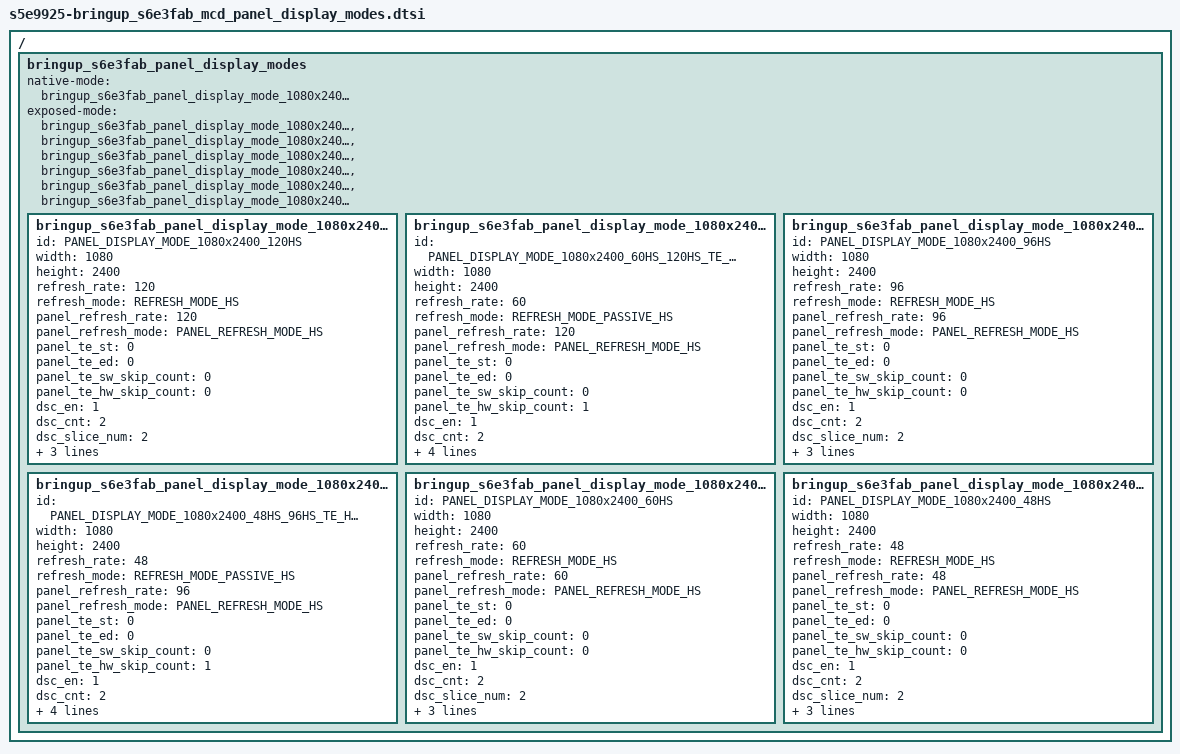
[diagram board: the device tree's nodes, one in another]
/*
 * SAMSUNG LCD Panel Device Tree Source
 *
 * Copyright (c) 2020 Samsung Electronics Co., Ltd.
 *		http://www.samsung.com
 *
 * This program is free software; you can redistribute it and/or modify
 * it under the terms of the GNU General Public License version 2 as
 * published by the Free Software Foundation.
 */

#include <dt-bindings/display/panel-display.h>

/ {
	fragment@panel_display_mode {
		target-path = "/";
		__overlay__ {
			bringup_s6e3fab_panel_display_modes:
			bringup_s6e3fab_panel_display_modes {
				native-mode = <&bringup_s6e3fab_panel_display_mode_1080x2400_120hs>;
				exposed-mode = <
					&bringup_s6e3fab_panel_display_mode_1080x2400_120hs
					&bringup_s6e3fab_panel_display_mode_1080x2400_60hs_120hs
					&bringup_s6e3fab_panel_display_mode_1080x2400_96hs
					&bringup_s6e3fab_panel_display_mode_1080x2400_48hs_96hs
					&bringup_s6e3fab_panel_display_mode_1080x2400_60hs
					&bringup_s6e3fab_panel_display_mode_1080x2400_48hs
				>;

				/* fhd */
				bringup_s6e3fab_panel_display_mode_1080x2400_120hs:
				bringup_s6e3fab_panel_display_mode_1080x2400_120hs {
					id = PANEL_DISPLAY_MODE_1080x2400_120HS;
					width = <1080>;
					height = <2400>;
					/* timing parameters */
					refresh_rate = <120>;			/* logical refresh rate */
					refresh_mode = <REFRESH_MODE_HS>;
					panel_refresh_rate = <120>;		/* panel internal refresh rate */
					panel_refresh_mode = <PANEL_REFRESH_MODE_HS>;
					panel_te_st = <0>;				/* te rising */
					panel_te_ed = <0>;				/* te falling */
					panel_te_sw_skip_count = <0>;	/* s/w te modulation */
					panel_te_hw_skip_count = <0>;	/* h/w te modulation */
					/* dsc parameters */
					dsc_en = <1>;			/* 0:Disable, 1:Enable */
					dsc_cnt = <2>;			/* used DSC count */
					dsc_slice_num = <2>;	/* count of dsc slice */
					dsc_slice_w = <540>;	/* width of dsc slice */
					dsc_slice_h = <120>;	/* height of dsc slice */
					/* dsi parameters */
					cmd_lp_ref = <3337>;
				};

				bringup_s6e3fab_panel_display_mode_1080x2400_60hs_120hs:
				bringup_s6e3fab_panel_display_mode_1080x2400_60hs_120hs {
					id = PANEL_DISPLAY_MODE_1080x2400_60HS_120HS_TE_HW_SKIP_1;
					width = <1080>;
					height = <2400>;
					/* timing parameters */
					refresh_rate = <60>;			/* logical refresh rate */
					refresh_mode = <REFRESH_MODE_PASSIVE_HS>;
					panel_refresh_rate = <120>;		/* panel internal refresh rate */
					panel_refresh_mode = <PANEL_REFRESH_MODE_HS>;
					panel_te_st = <0>;				/* te rising */
					panel_te_ed = <0>;				/* te falling */
					panel_te_sw_skip_count = <0>;	/* s/w te modulation */
					panel_te_hw_skip_count = <1>;	/* h/w te modulation */
					/* dsc parameters */
					dsc_en = <1>;			/* 0:Disable, 1:Enable */
					dsc_cnt = <2>;			/* used DSC count */
					dsc_slice_num = <2>;	/* count of dsc slice */
					dsc_slice_w = <540>;	/* width of dsc slice */
					dsc_slice_h = <120>;	/* height of dsc slice */
					/* dsi parameters */
					cmd_lp_ref = <3337>;
				};

				bringup_s6e3fab_panel_display_mode_1080x2400_96hs:
				bringup_s6e3fab_panel_display_mode_1080x2400_96hs {
					id = PANEL_DISPLAY_MODE_1080x2400_96HS;
					width = <1080>;
					height = <2400>;
					/* timing parameters */
					refresh_rate = <96>;			/* logical refresh rate */
					refresh_mode = <REFRESH_MODE_HS>;
					panel_refresh_rate = <96>;		/* panel internal refresh rate */
					panel_refresh_mode = <PANEL_REFRESH_MODE_HS>;
					panel_te_st = <0>;				/* te rising */
					panel_te_ed = <0>;				/* te falling */
					panel_te_sw_skip_count = <0>;	/* s/w te modulation */
					panel_te_hw_skip_count = <0>;	/* h/w te modulation */
					/* dsc parameters */
					dsc_en = <1>;			/* 0:Disable, 1:Enable */
					dsc_cnt = <2>;			/* used DSC count */
					dsc_slice_num = <2>;	/* count of dsc slice */
					dsc_slice_w = <540>;	/* width of dsc slice */
					dsc_slice_h = <120>;	/* height of dsc slice */
					/* dsi parameters */
					cmd_lp_ref = <5093>;
				};

				bringup_s6e3fab_panel_display_mode_1080x2400_48hs_96hs:
				bringup_s6e3fab_panel_display_mode_1080x2400_48hs_96hs {
					id = PANEL_DISPLAY_MODE_1080x2400_48HS_96HS_TE_HW_SKIP_1;
					width = <1080>;
					height = <2400>;
					/* timing parameters */
					refresh_rate = <48>;			/* logical refresh rate */
					refresh_mode = <REFRESH_MODE_PASSIVE_HS>;
					panel_refresh_rate = <96>;		/* panel internal refresh rate */
					panel_refresh_mode = <PANEL_REFRESH_MODE_HS>;
					panel_te_st = <0>;				/* te rising */
					panel_te_ed = <0>;				/* te falling */
					panel_te_sw_skip_count = <0>;	/* s/w te modulation */
					panel_te_hw_skip_count = <1>;	/* h/w te modulation */
					/* dsc parameters */
					dsc_en = <1>;			/* 0:Disable, 1:Enable */
					dsc_cnt = <2>;			/* used DSC count */
					dsc_slice_num = <2>;	/* count of dsc slice */
					dsc_slice_w = <540>;	/* width of dsc slice */
					dsc_slice_h = <120>;	/* height of dsc slice */
					/* dsi parameters */
					cmd_lp_ref = <5093>;
				};

				bringup_s6e3fab_panel_display_mode_1080x2400_60hs:
				bringup_s6e3fab_panel_display_mode_1080x2400_60hs {
					id = PANEL_DISPLAY_MODE_1080x2400_60HS;
					width = <1080>;
					height = <2400>;
					/* timing parameters */
					refresh_rate = <60>;			/* logical refresh rate */
					refresh_mode = <REFRESH_MODE_HS>;
					panel_refresh_rate = <60>;		/* panel internal refresh rate */
					panel_refresh_mode = <PANEL_REFRESH_MODE_HS>;
					panel_te_st = <0>;				/* te rising */
					panel_te_ed = <0>;				/* te falling */
					panel_te_sw_skip_count = <0>;	/* s/w te modulation */
					panel_te_hw_skip_count = <0>;	/* h/w te modulation */
					/* dsc parameters */
					dsc_en = <1>;			/* 0:Disable, 1:Enable */
					dsc_cnt = <2>;			/* used DSC count */
					dsc_slice_num = <2>;	/* count of dsc slice */
					dsc_slice_w = <540>;	/* width of dsc slice */
					dsc_slice_h = <120>;	/* height of dsc slice */
					/* dsi parameters */
					cmd_lp_ref = <10361>;
				};

				bringup_s6e3fab_panel_display_mode_1080x2400_48hs:
				bringup_s6e3fab_panel_display_mode_1080x2400_48hs {
					id = PANEL_DISPLAY_MODE_1080x2400_48HS;
					width = <1080>;
					height = <2400>;
					/* timing parameters */
					refresh_rate = <48>;			/* logical refresh rate */
					refresh_mode = <REFRESH_MODE_HS>;
					panel_refresh_rate = <48>;		/* panel internal refresh rate */
					panel_refresh_mode = <PANEL_REFRESH_MODE_HS>;
					panel_te_st = <0>;				/* te rising */
					panel_te_ed = <0>;				/* te falling */
					panel_te_sw_skip_count = <0>;	/* s/w te modulation */
					panel_te_hw_skip_count = <0>;	/* h/w te modulation */
					/* dsc parameters */
					dsc_en = <1>;			/* 0:Disable, 1:Enable */
					dsc_cnt = <2>;			/* used DSC count */
					dsc_slice_num = <2>;	/* count of dsc slice */
					dsc_slice_w = <540>;	/* width of dsc slice */
					dsc_slice_h = <120>;	/* height of dsc slice */
					/* dsi parameters */
					cmd_lp_ref = <13873>;
				};
			};
		};
	};
};
